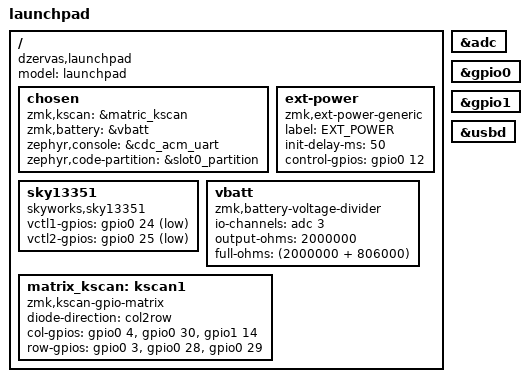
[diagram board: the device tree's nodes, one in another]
/*
 * Copyright (c) 2020 The ZMK Contributors
 *
 * SPDX-License-Identifier: MIT
 */

/dts-v1/;
#include <nordic/nrf52840_qiaa.dtsi>
#include <dt-bindings/zmk/matrix_transform.h>
#include "launchpad_mcuboot.overlay"

/ {
	model = "launchpad";
	compatible = "dzervas,launchpad";

	chosen {
		zmk,kscan = &matric_kscan;
		zmk,battery = &vbatt;
		zephyr,console = &cdc_acm_uart;
		zephyr,code-partition = &slot0_partition;
	};

	ext-power {
		compatible = "zmk,ext-power-generic";
		label = "EXT_POWER";
		init-delay-ms = <50>;
		control-gpios = <&gpio0 12 GPIO_ACTIVE_HIGH>;
	};

	sky13351 {
		compatible = "skyworks,sky13351";
		vctl1-gpios = <&gpio0 24 GPIO_ACTIVE_LOW>;
		vctl2-gpios = <&gpio0 25 GPIO_ACTIVE_LOW>;
	};

	vbatt:vbatt {
		compatible = "zmk,battery-voltage-divider";
		// label = "BATTERY";
		io-channels = <&adc 3>;
		output-ohms = <2000000>;
		full-ohms = <(2000000 + 806000)>;
	};

	matrix_kscan: kscan1 {
		compatible = "zmk,kscan-gpio-matrix";
		// label = "MATRIX_KSCAN";
		diode-direction = "col2row";

		col-gpios
			= <&gpio0 4 GPIO_ACTIVE_HIGH>
			, <&gpio0 30 GPIO_ACTIVE_HIGH>
			, <&gpio1 14 GPIO_ACTIVE_HIGH>
			;
		row-gpios
			= <&gpio0 3 (GPIO_ACTIVE_HIGH | GPIO_PULL_DOWN)>
			, <&gpio0 28 (GPIO_ACTIVE_HIGH | GPIO_PULL_DOWN)>
			, <&gpio0 29 (GPIO_ACTIVE_HIGH | GPIO_PULL_DOWN)>
			;
	};
};

&adc {
	status = "okay";
};

&gpio0 {
	status = "okay";
};

&gpio1 {
	status = "okay";
};

&usbd {
	status = "okay";
};
